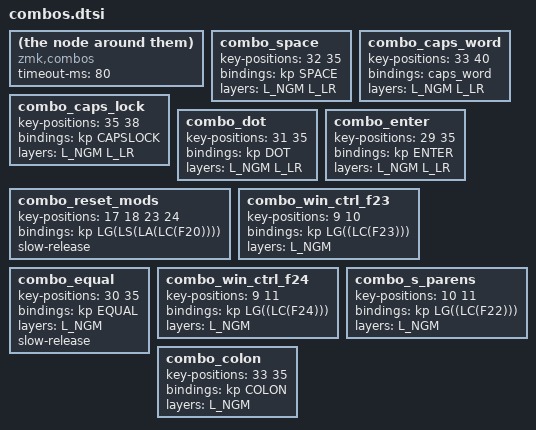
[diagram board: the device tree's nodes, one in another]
 // COMBOS - aka CHORDS
 
// #include <dt-bindings/zmk/keys.h>

/*  KEYMAP ref ##s
 * https://github.com/KinesisCorporation/Adv360-Pro-ZMK/blob/V3.0/assets/key-positions.png 
 * NEW v3 : THUMBs moved into normal rows
 *
 *  0  1  2  3  4  5  6                            7  8  9  10 11 12 13
 *  14 15 16 17 18 19 20                           21 22 23 24 25 26 27
 *  28 29 30 31 32 33 34         35 36  37 38      39 40 41 42 43 44 45
 *  46 47 48 49 50 51               52  53            54 55 56 57 58 59
 *  60 61 62 63 64            65 66 67  68 69 70         71 72 73 74 75
*/


 /* NOTES
    https://zmk.dev/docs/features/combos
    https://zmk.dev/docs/config/combos

    timeout-ms: must hit combo w/in that time
    layers = <0 1 ...> // OPTIONAL - to restrict combo to only work on that/those layers

 */

 /* #DEFs...  see adv360.keymap : this file included below the #defs */

compatible = "zmk,combos";
timeout-ms = <80>;

// [A] SPACE
combo_space {
    key-positions = <32 35>; // L-index, L-thumb
    bindings = <&kp SPACE>;
    layers = <L_NGM L_LR>;
};

// [B] CAPS-WORD
combo_caps_word {
key-positions = <33 40>; // {RH-index-in-1; LH-index-in-1}
bindings = <&caps_word>;
layers = <L_NGM L_LR>;
};

// [C] CAPS-LOCK
combo_caps_lock {
    key-positions = <35 38>; // Both top/inner smaller thumb keys (currently each assigned to Shift)
    bindings = <&kp CAPSLOCK>;
    layers = <L_NGM L_LR>;
};

// [D] PERIOD
combo_dot {
    key-positions = <31 35>; // L-middle, L-thumb
    bindings = <&kp DOT>;
    layers = <L_NGM L_LR>;
};

// [E] ENTER
combo_enter {
    key-positions = <29 35>; // L-pinkie, L-thumb
    bindings = <&kp ENTER>;
    layers = <L_NGM L_LR>;
};

// [F] RESET MODs when stuck / ▣ 2025-02-09 / WIP / NOT WORKING WELL
combo_reset_mods {
    key-positions = <17 18 23 24>; // RH+LH 2 inner fingers 1 row up
    bindings = <&kp LG(LS(LA(LC(F20))))>; // SEE AHK
    //layers = <L_NGM>; - ALL
    slow-release; // optional - seems will only fire combo after ALL are released / 2025-03-27 TBD - will help prevent stuck mods?
};

// [G] "..." - Win+Ctrl+F23 / AHK: "..." (separate, Ø … char)
combo_win_ctrl_f23 {
    key-positions = <9 10>; // top row (.
    bindings = <&kp LG((LC(F23)))>; // SEE AHK
    layers = <L_NGM>;
};

// [H] =
combo_equal {
    key-positions = <30 35>; // L-index+1, L-thumb
    bindings = <&kp EQUAL>;
    layers = <L_NGM>;
    slow-release; // optional - seems will only fire combo after ALL are released
};

// [I] - Win+Ctrl+F24 / AHK: "(){Left}"
combo_win_ctrl_f24 {
    key-positions = <9 11>; // top row ()
    bindings = <&kp LG((LC(F24)))>; // SEE AHK
    layers = <L_NGM>;
};

// [J] "(s)"
combo_s_parens {
    key-positions = <10 11>; // top row .)
    bindings = <&kp LG((LC(F22)))>; // SEE AHK
    layers = <L_NGM>;
};

// [K] COLON (:)
combo_colon {
    key-positions = <33 35>; // L-; + L-thumb
    bindings = <&kp COLON>;
    layers = <L_NGM>;
};


/* 2025-03-27+ unused
// C4a
combo_context_menu_lh {
    key-positions = <35 36>; // LH, top-2 thumb keys
    bindings = <&kp K_CONTEXT_MENU>;
    layers = <L_LR>;
};
// C4b
combo_context_menu_rh {
    key-positions = <37 38>; // RH, top-2 thumb keys
    bindings = <&kp K_CONTEXT_MENU>;
    layers = <L_LR>;
};
*/



